# STM32F030xC register map
File version: 1.0
Registers are 32-bit, read-write, reset 0x0 unless marked. A register's access mark holds for its fields unless they carry their own. Offsets are from the block's base; [hi:lo] are bit positions; 'fields as' and 'values as' point back to an identical list.

## USART4 — Universal Synchronous Asynchronous Receiver Transmitter
Base 0x40004C00
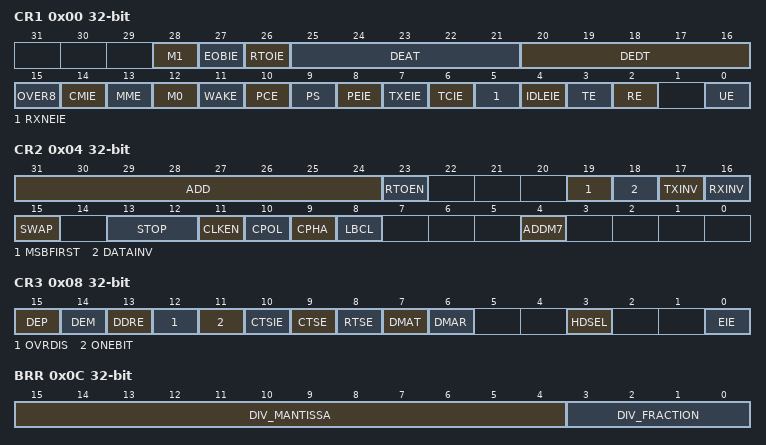
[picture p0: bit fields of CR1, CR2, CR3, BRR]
0x00 CR1 — USART Control register 1
  [28] M1 — Word length bit 1
  [27] EOBIE — End of Block interrupt enable
  [26] RTOIE — Receive Time Out interrupt enable
  [25:21] DEAT — DEAT[4:0] bits (Driver Enable Assertion Time)
  [20:16] DEDT — DEDT[4:0] bits (Driver Enable Deassertion Time)
  [15] OVER8 — Oversampling by 8-bit or 16-bit mode
    0=OVERSAMPLING_16 (Oversampling by 16); 1=OVERSAMPLING_8 (Oversampling by 8)
  [14] CMIE — Character match interrupt enable
  [13] MME — Mute Mode Enable
  [12] M0 — Word length bit 0
  [11] WAKE — Receiver Wakeup method
    0=IDLELINE (USART wake up from Mute mode on Idle Line); 1=ADDRESSMARK (USART wake up from Mute mode on Address Mark)
  [10] PCE — Parity Control Enable
  [9] PS — Parity Selection
  [8] PEIE — PE Interrupt Enable
  [7] TXEIE — TXE Interrupt Enable
  [6] TCIE — Transmission Complete Interrupt Enable
  [5] RXNEIE — RXNE Interrupt Enable
  [4] IDLEIE — IDLE Interrupt Enable
  [3] TE — Transmitter Enable
  [2] RE — Receiver Enable
  [0] UE — USART Enable
0x04 CR2 — USART Control register 2
  [31:24] ADD — Address of the USART node
  [23] RTOEN — Receiver Time-Out enable
  [19] MSBFIRST — Most Significant Bit First
    0=LSBFIRST (data is transmitted/received with data bit 0 first, following the start bit); 1=MSBFIRST (data is transmitted/received with the MSB first, following the start bit)
  [18] DATAINV — Binary data inversion
    0=POSITIVE (Logical data from the data register are send/received in positive/direct logic. (1=H, 0=L)); 1=NEGATIVE (Logical data from the data register are send/received in negative/inverse logic. (1=L, 0=H). The parity bit is also inverted.)
  [17] TXINV — TX pin active level inversion
    0=STANDARD (TX pin signal works using the standard logic levels); 1=INVERTED (TX pin signal values are inverted.)
  [16] RXINV — RX pin active level inversion
    0=STANDARD (RX pin signal works using the standard logic levels); 1=INVERTED (RX pin signal values are inverted.)
  [15] SWAP — SWAP TX/RX pins
    0=STANDARD (TX/RX pins are used as defined in standard pinout); 1=SWAPPED (TX and RX pins functions are swapped.)
  [13:12] STOP — STOP[1:0] bits (STOP bits)
    0=STOPBITS_1 (1 stop bit); 2=STOPBITS_2 (2 stop bits)
  [11] CLKEN — Clock Enable
  [10] CPOL — Clock Polarity
    0=LOW (Steady low value on SCLK pin outside transmission window); 1=HIGH (Steady high value on SCLK pin outside transmission window)
  [9] CPHA — Clock Phase
    0=PHASE_1EDGE (The first clock transition is the first data capture edge); 1=PHASE_2EDGE (The second clock transition is the first data capture edge)
  [8] LBCL — Last Bit Clock pulse
    0=NO_OUTPUT (The clock pulse of the last data bit is not output to the SCLK pin); 1=OUTPUT (The clock pulse of the last data bit is output to the SCLK pin)
  [4] ADDM7 — 7-bit or 4-bit Address Detection
    0=DETECT_4B (4-bit address detection method selected); 1=DETECT_7B (7-bit address detection (in 8-bit data mode) method selected)
0x08 CR3 — USART Control register 3
  [15] DEP — Driver Enable Polarity Selection
    0=HIGH (DE signal is active high); 1=LOW (DE signal is active low)
  [14] DEM — Driver Enable Mode
  [13] DDRE — DMA Disable on Reception Error
  [12] OVRDIS — Overrun Disable
  [11] ONEBIT — One sample bit method enable
  [10] CTSIE — CTS Interrupt Enable
  [9] CTSE — CTS Enable
  [8] RTSE — RTS Enable
  [7] DMAT — DMA Enable Transmitter
  [6] DMAR — DMA Enable Receiver
  [3] HDSEL — Half-Duplex Selection
  [0] EIE — Error Interrupt Enable
0x0C BRR — USART Baud rate register
  [15:4] DIV_MANTISSA — Mantissa of USARTDIV
  [3:0] DIV_FRACTION — Fraction of USARTDIV
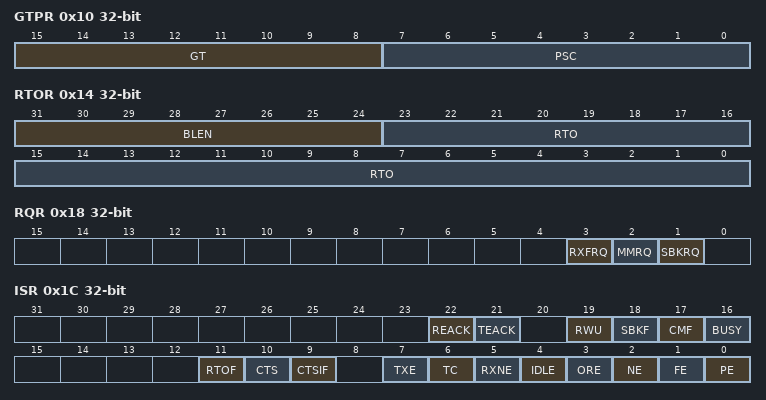
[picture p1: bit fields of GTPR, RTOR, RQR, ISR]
0x10 GTPR — USART Guard time and prescaler register
  [15:8] GT — GT[7:0] bits (Guard time value)
  [7:0] PSC — PSC[7:0] bits (Prescaler value)
0x14 RTOR — USART Receiver Time Out register
  [31:24] BLEN — Block Length
  [23:0] RTO — Receiver Time Out Value
0x18 RQR — USART Request register
  [3] RXFRQ — Receive Data flush Request
  [2] MMRQ — Mute Mode Request
  [1] SBKRQ — Send Break Request
0x1C ISR — USART Interrupt and status register
  [22] REACK — Receive Enable Acknowledge Flag
  [21] TEACK — Transmit Enable Acknowledge Flag
  [19] RWU — Receive Wake Up from mute mode Flag
  [18] SBKF — Send Break Flag
  [17] CMF — Character Match Flag
  [16] BUSY — Busy Flag
  [11] RTOF — Receiver Time Out
  [10] CTS — CTS flag
  [9] CTSIF — CTS interrupt flag
  [7] TXE — Transmit Data Register Empty
  [6] TC — Transmission Complete
  [5] RXNE — Read Data Register Not Empty
  [4] IDLE — IDLE line detected
  [3] ORE — OverRun Error
  [2] NE — Noise detected Flag
  [1] FE — Framing Error
  [0] PE — Parity Error
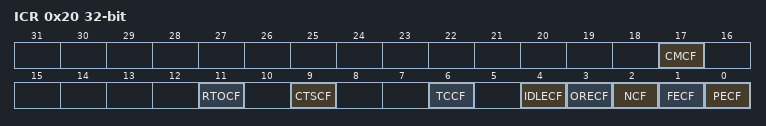
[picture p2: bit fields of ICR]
0x20 ICR — USART Interrupt flag Clear register
  [17] CMCF — Character Match Clear Flag
  [11] RTOCF — Receiver Time Out Clear Flag
  [9] CTSCF — CTS Interrupt Clear Flag
  [6] TCCF — Transmission Complete Clear Flag
  [4] IDLECF — IDLE line detected Clear Flag
  [3] ORECF — OverRun Error Clear Flag
  [2] NCF — Noise detected Clear Flag
  [1] FECF — Framing Error Clear Flag
  [0] PECF — Parity Error Clear Flag
0x24 RDR 16-bit — USART Receive Data register
0x28 TDR 16-bit — USART Transmit Data register

## USART5 — Universal Synchronous Asynchronous Receiver Transmitter
Base 0x40005000
Registers as USART4; these are added or differ:
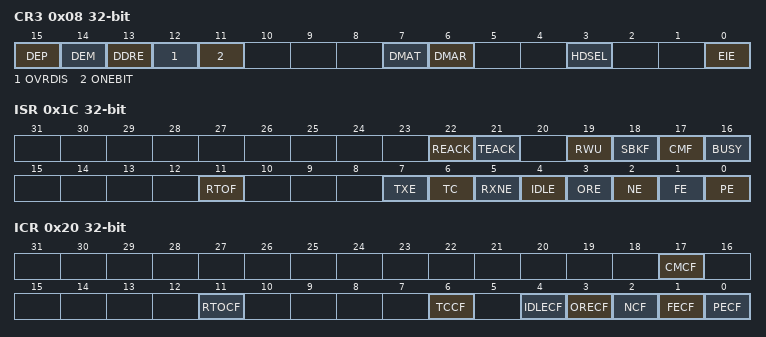
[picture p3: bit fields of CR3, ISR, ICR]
0x08 CR3 — USART Control register 3
  [15] DEP — Driver Enable Polarity Selection
    0=HIGH (DE signal is active high); 1=LOW (DE signal is active low)
  [14] DEM — Driver Enable Mode
  [13] DDRE — DMA Disable on Reception Error
  [12] OVRDIS — Overrun Disable
  [11] ONEBIT — One sample bit method enable
  [7] DMAT — DMA Enable Transmitter
  [6] DMAR — DMA Enable Receiver
  [3] HDSEL — Half-Duplex Selection
  [0] EIE — Error Interrupt Enable
0x1C ISR — USART Interrupt and status register
  [22] REACK — Receive Enable Acknowledge Flag
  [21] TEACK — Transmit Enable Acknowledge Flag
  [19] RWU — Receive Wake Up from mute mode Flag
  [18] SBKF — Send Break Flag
  [17] CMF — Character Match Flag
  [16] BUSY — Busy Flag
  [11] RTOF — Receiver Time Out
  [7] TXE — Transmit Data Register Empty
  [6] TC — Transmission Complete
  [5] RXNE — Read Data Register Not Empty
  [4] IDLE — IDLE line detected
  [3] ORE — OverRun Error
  [2] NE — Noise detected Flag
  [1] FE — Framing Error
  [0] PE — Parity Error
0x20 ICR — USART Interrupt flag Clear register
  [17] CMCF — Character Match Clear Flag
  [11] RTOCF — Receiver Time Out Clear Flag
  [6] TCCF — Transmission Complete Clear Flag
  [4] IDLECF — IDLE line detected Clear Flag
  [3] ORECF — OverRun Error Clear Flag
  [2] NCF — Noise detected Clear Flag
  [1] FECF — Framing Error Clear Flag
  [0] PECF — Parity Error Clear Flag

## USART6 — Universal Synchronous Asynchronous Receiver Transmitter
Base 0x40011400
Registers as USART5; these are added or differ:
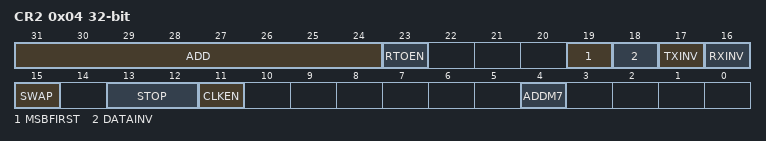
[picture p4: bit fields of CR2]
0x04 CR2 — USART Control register 2
  [31:24] ADD — Address of the USART node
  [23] RTOEN — Receiver Time-Out enable
  [19] MSBFIRST — Most Significant Bit First
    0=LSBFIRST (data is transmitted/received with data bit 0 first, following the start bit); 1=MSBFIRST (data is transmitted/received with the MSB first, following the start bit)
  [18] DATAINV — Binary data inversion
    values as USART4.CR2.DATAINV
  [17] TXINV — TX pin active level inversion
    0=STANDARD (TX pin signal works using the standard logic levels); 1=INVERTED (TX pin signal values are inverted.)
  [16] RXINV — RX pin active level inversion
    0=STANDARD (RX pin signal works using the standard logic levels); 1=INVERTED (RX pin signal values are inverted.)
  [15] SWAP — SWAP TX/RX pins
    0=STANDARD (TX/RX pins are used as defined in standard pinout); 1=SWAPPED (TX and RX pins functions are swapped.)
  [13:12] STOP — STOP[1:0] bits (STOP bits)
    0=STOPBITS_1 (1 stop bit); 2=STOPBITS_2 (2 stop bits)
  [11] CLKEN — Clock Enable
  [4] ADDM7 — 7-bit or 4-bit Address Detection
    0=DETECT_4B (4-bit address detection method selected); 1=DETECT_7B (7-bit address detection (in 8-bit data mode) method selected)
